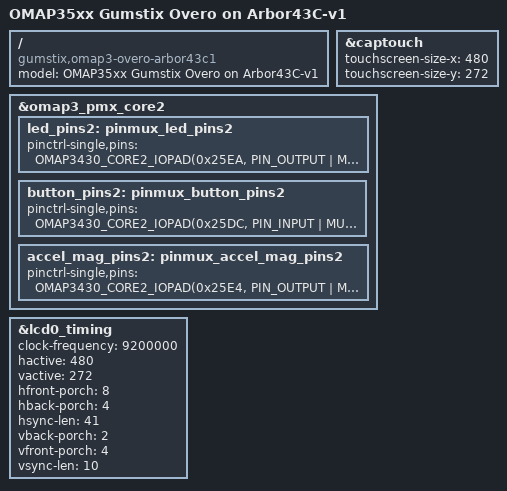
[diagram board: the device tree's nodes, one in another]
/*
 * Copyright (C) 2015 Gumstix, Inc. - https://www.gumstix.com/
 *
 * This program is free software; you can redistribute it and/or modify
 * it under the terms of the GNU General Public License version 2 as
 * published by the Free Software Foundation.
 */

/*
 * Arbor43C expansion board is manufactured by Gumstix Inc.
 * This is for the 2nd revision of the board (v1)
 */

/dts-v1/;

#include "omap3-overo.dtsi"
#include "omap3-overo-arbor57c-common.dtsi"

/ {
	model = "OMAP35xx Gumstix Overo on Arbor43C-v1";
	compatible = "gumstix,omap3-overo-arbor43c1", "gumstix,omap3-overo", "ti,omap3430", "ti,omap3";
};

&captouch {
	touchscreen-size-x = <480>;
	touchscreen-size-y = <272>;
};  

&omap3_pmx_core2 {
	led_pins2: pinmux_led_pins2 {
		pinctrl-single,pins = <
			OMAP3430_CORE2_IOPAD(0x25EA, PIN_OUTPUT | MUX_MODE4)    /* etx_d7.gpio_21 */
			OMAP3430_CORE2_IOPAD(0x25EC, PIN_OUTPUT | MUX_MODE4)    /* etx_d8.gpio_22 */
		>;
	};

	button_pins2: pinmux_button_pins2 {
		pinctrl-single,pins = <
			OMAP3430_CORE2_IOPAD(0x25DC, PIN_INPUT | MUX_MODE4)    /* etx_d0.gpio_14 */
		>;
	};

	accel_mag_pins2: pinmux_accel_mag_pins2 {
		pinctrl-single,pins = <
			OMAP3430_CORE2_IOPAD(0x25E4, PIN_OUTPUT | MUX_MODE4)    /* etx_d4.gpio_18 */
		>;
	};
};

&lcd0_timing {
	clock-frequency = <9200000>;
	hactive = <480>;
	vactive = <272>;
	hfront-porch = <8>;
	hback-porch = <4>;
	hsync-len = <41>;
	vback-porch = <2>;
	vfront-porch = <4>;
	vsync-len = <10>;
};
